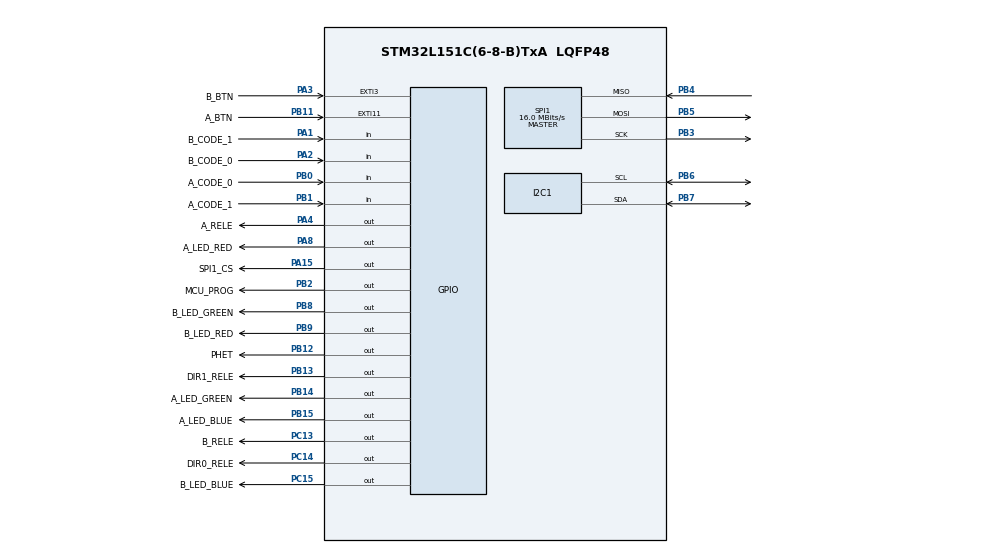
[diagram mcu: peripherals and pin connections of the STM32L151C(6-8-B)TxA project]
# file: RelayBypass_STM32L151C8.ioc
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Mcu.Family=STM32L1
PH0-OSC_IN.Signal=RCC_OSC_IN
SPI1.VirtualType=VM_MASTER
PB14.GPIO_Label=A_LED_GREEN
NVIC.EXTI3_IRQn=true\:1\:0\:true\:false\:true\:true\:true
PB0.GPIO_Label=A_CODE_0
PB13.GPIO_Label=DIR1_RELE
PB11.Signal=GPXTI11
PB13.Signal=GPIO_Output
PB15.Signal=GPIO_Output
PC15-OSC32_OUT.GPIO_Label=B_LED_BLUE
RCC.SYSCLKSource=RCC_SYSCLKSOURCE_PLLCLK
ProjectManager.StackSize=0x400
PA15.GPIO_Label=SPI1_CS
SPI1.Direction=SPI_DIRECTION_2LINES
RCC.HCLKFreq_Value=32000000
PC13-WKUP2.GPIO_Label=B_RELE
RCC.APB2TimFreq_Value=32000000
PB6.Signal=I2C1_SCL
PB6.Mode=I2C
SPI1.CalculateBaudRate=16.0 MBits/s
RCC.AHBFreq_Value=32000000
PH0-OSC_IN.Mode=HSE-External-Oscillator
NVIC.EXTI15_10_IRQn=true\:1\:0\:true\:false\:true\:true\:true
RCC.HSE_VALUE=8000000
PC13-WKUP2.Signal=GPIO_Output
PB2.Signal=GPIO_Output
PB3.Mode=Full_Duplex_Master
RCC.PLLMUL=RCC_PLL_MUL8
PB12.GPIO_Label=PHET
PB4.Mode=Full_Duplex_Master
PA14.Mode=Serial_Wire
PB1.GPIO_Label=A_CODE_1
PB5.Mode=Full_Duplex_Master
NVIC.TIM2_IRQn=true\:0\:0\:false\:false\:true\:true\:true
PB7.Signal=I2C1_SDA
PA8.Signal=GPIO_Output
PH1-OSC_OUT.Mode=HSE-External-Oscillator
Mcu.Package=LQFP48
PB9.Signal=GPIO_Output
TIM2.Prescaler=32000
PB1.Signal=GPIO_Input
PA2.GPIO_Label=B_CODE_0
PA15.Signal=GPIO_Output
RCC.APB1TimFreq_Value=32000000
PC14-OSC32_IN.GPIO_Label=DIR0_RELE
PA4.GPIO_Label=A_RELE
PB4.Signal=SPI1_MISO
PA3.Signal=GPXTI3
RCC.MSI_VALUE=2097000
RCC.PLLSourceVirtual=RCC_PLLSOURCE_HSE
PB9.GPIO_Label=B_LED_RED
PB11.GPIO_Label=A_BTN
PC14-OSC32_IN.Signal=GPIO_Output
PA13.Signal=SYS_JTMS-SWDIO
PB8.GPIO_Label=B_LED_GREEN
PA8.GPIO_Label=A_LED_RED
ProjectManager.TargetToolchain=STM32CubeIDE
RCC.LSE_VALUE=32768
PC15-OSC32_OUT.Signal=GPIO_Output
PA1.Signal=GPIO_Input
PB14.Signal=GPIO_Output
board=custom
RCC.VCOOutputFreq_Value=64000000
RCC.APB2Freq_Value=32000000
PB15.GPIO_Label=A_LED_BLUE
VP_TIM2_VS_ClockSourceINT.Mode=Internal
SPI1.Mode=SPI_MODE_MASTER
PA1.GPIO_Label=B_CODE_1
PH1-OSC_OUT.Signal=RCC_OSC_OUT
TIM2.Period=125
PA13.Mode=Serial_Wire
Mcu.Name=STM32L151C(6-8-B)TxA
PA2.Signal=GPIO_Input
RCC.48MHZClocksFreq_Value=32000000
PB3.Signal=SPI1_SCK
PA4.Signal=GPIO_Output
RCC.SYSCLKFreq_VALUE=32000000
PB5.Signal=SPI1_MOSI
PB7.Mode=I2C
PA14.Signal=SYS_JTCK-SWCLK
PB2.GPIO_Label=MCU_PROG
ProjectManager.HeapSize=0x200
RCC.HSI_VALUE=16000000
NVIC.PriorityGroup=NVIC_PRIORITYGROUP_4
PB8.Signal=GPIO_Output
TIM2.AutoReloadPreload=TIM_AUTORELOAD_PRELOAD_ENABLE
RCC.APB1Freq_Value=32000000
PB0.Signal=GPIO_Input
PB12.Signal=GPIO_Output
PA3.GPIO_Label=B_BTN

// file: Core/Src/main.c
/* USER CODE BEGIN Header */
/**
  ******************************************************************************
  * @file           : main.c
  * @brief          : Main program body
  ******************************************************************************
  * @attention
  *
  * <h2><center>&copy; Copyright (c) 2021 STMicroelectronics.
  * All rights reserved.</center></h2>
  *
  * This software component is licensed by ST under BSD 3-Clause license,
  * the "License"; You may not use this file except in compliance with the
  * License. You may obtain a copy of the License at:
  *                        opensource.org/licenses/BSD-3-Clause
  *
  ******************************************************************************
  */
/* USER CODE END Header */
#include "main.h"
#include "i2c.h"
#include "spi.h"
#include "tim.h"
#include "gpio.h"

/* USER CODE BEGIN Includes */
#include "../../../../SharedLibs/RelayBypass/Include/Executor.h"
/* USER CODE END Includes */

void SystemClock_Config(void);

int main(void)
{

  /* MCU Configuration--------------------------------------------------------*/

  /* Reset of all peripherals, Initializes the Flash interface and the Systick. */
  HAL_Init();

  /* Configure the system clock */
  SystemClock_Config();

  /* Initialize all configured peripherals */
  MX_GPIO_Init();
  MX_TIM2_Init();
  MX_I2C1_Init();
  MX_SPI1_Init();
  /* USER CODE BEGIN 2 */
  Status status = OK;

  Executor *pExecutor = Executor_Create();

  if(pExecutor == NULL)
  {
      Error_Handler();
  }

  /* USER CODE END 2 */

  /* Infinite loop */
  /* USER CODE BEGIN WHILE */
  while (1)
  {
    status = Executor_Handler(pExecutor);

    if (status == INVALID_PARAMETERS)
    {
        Error_Handler();
    }
    /* USER CODE END WHILE */

  }
}

void SystemClock_Config(void)
{

  LL_FLASH_Enable64bitAccess();

  LL_FLASH_SetLatency(LL_FLASH_LATENCY_1);
  while(LL_FLASH_GetLatency()!= LL_FLASH_LATENCY_1)
  {
  }
  LL_PWR_SetRegulVoltageScaling(LL_PWR_REGU_VOLTAGE_SCALE1);
  LL_RCC_HSE_Enable();

   /* Wait till HSE is ready */
  while(LL_RCC_HSE_IsReady() != 1)
  {

  }
  LL_RCC_PLL_ConfigDomain_SYS(LL_RCC_PLLSOURCE_HSE, LL_RCC_PLL_MUL_8, LL_RCC_PLL_DIV_2);
  LL_RCC_PLL_Enable();

   /* Wait till PLL is ready */
  while(LL_RCC_PLL_IsReady() != 1)
  {

  }
  LL_RCC_SetAHBPrescaler(LL_RCC_SYSCLK_DIV_1);
  LL_RCC_SetAPB1Prescaler(LL_RCC_APB1_DIV_1);
  LL_RCC_SetAPB2Prescaler(LL_RCC_APB2_DIV_1);
  LL_RCC_SetSysClkSource(LL_RCC_SYS_CLKSOURCE_PLL);

   /* Wait till System clock is ready */
  while(LL_RCC_GetSysClkSource() != LL_RCC_SYS_CLKSOURCE_STATUS_PLL)
  {

  }
  LL_SetSystemCoreClock(32000000);

   /* Update the time base */
  if (HAL_InitTick (TICK_INT_PRIORITY) != HAL_OK)
  {
    Error_Handler();
  }
}

void Error_Handler(void)
{
  /* USER CODE BEGIN Error_Handler_Debug */
  /* User can add his own implementation to report the HAL error return state */
  __disable_irq();
  Interface_ToggleChannel(CHANNEL_A);
  Interface_ToggleChannel(CHANNEL_B);
  NVIC_SystemReset();
  /* USER CODE END Error_Handler_Debug */
}

/************************ (C) COPYRIGHT STMicroelectronics *****END OF FILE****/
